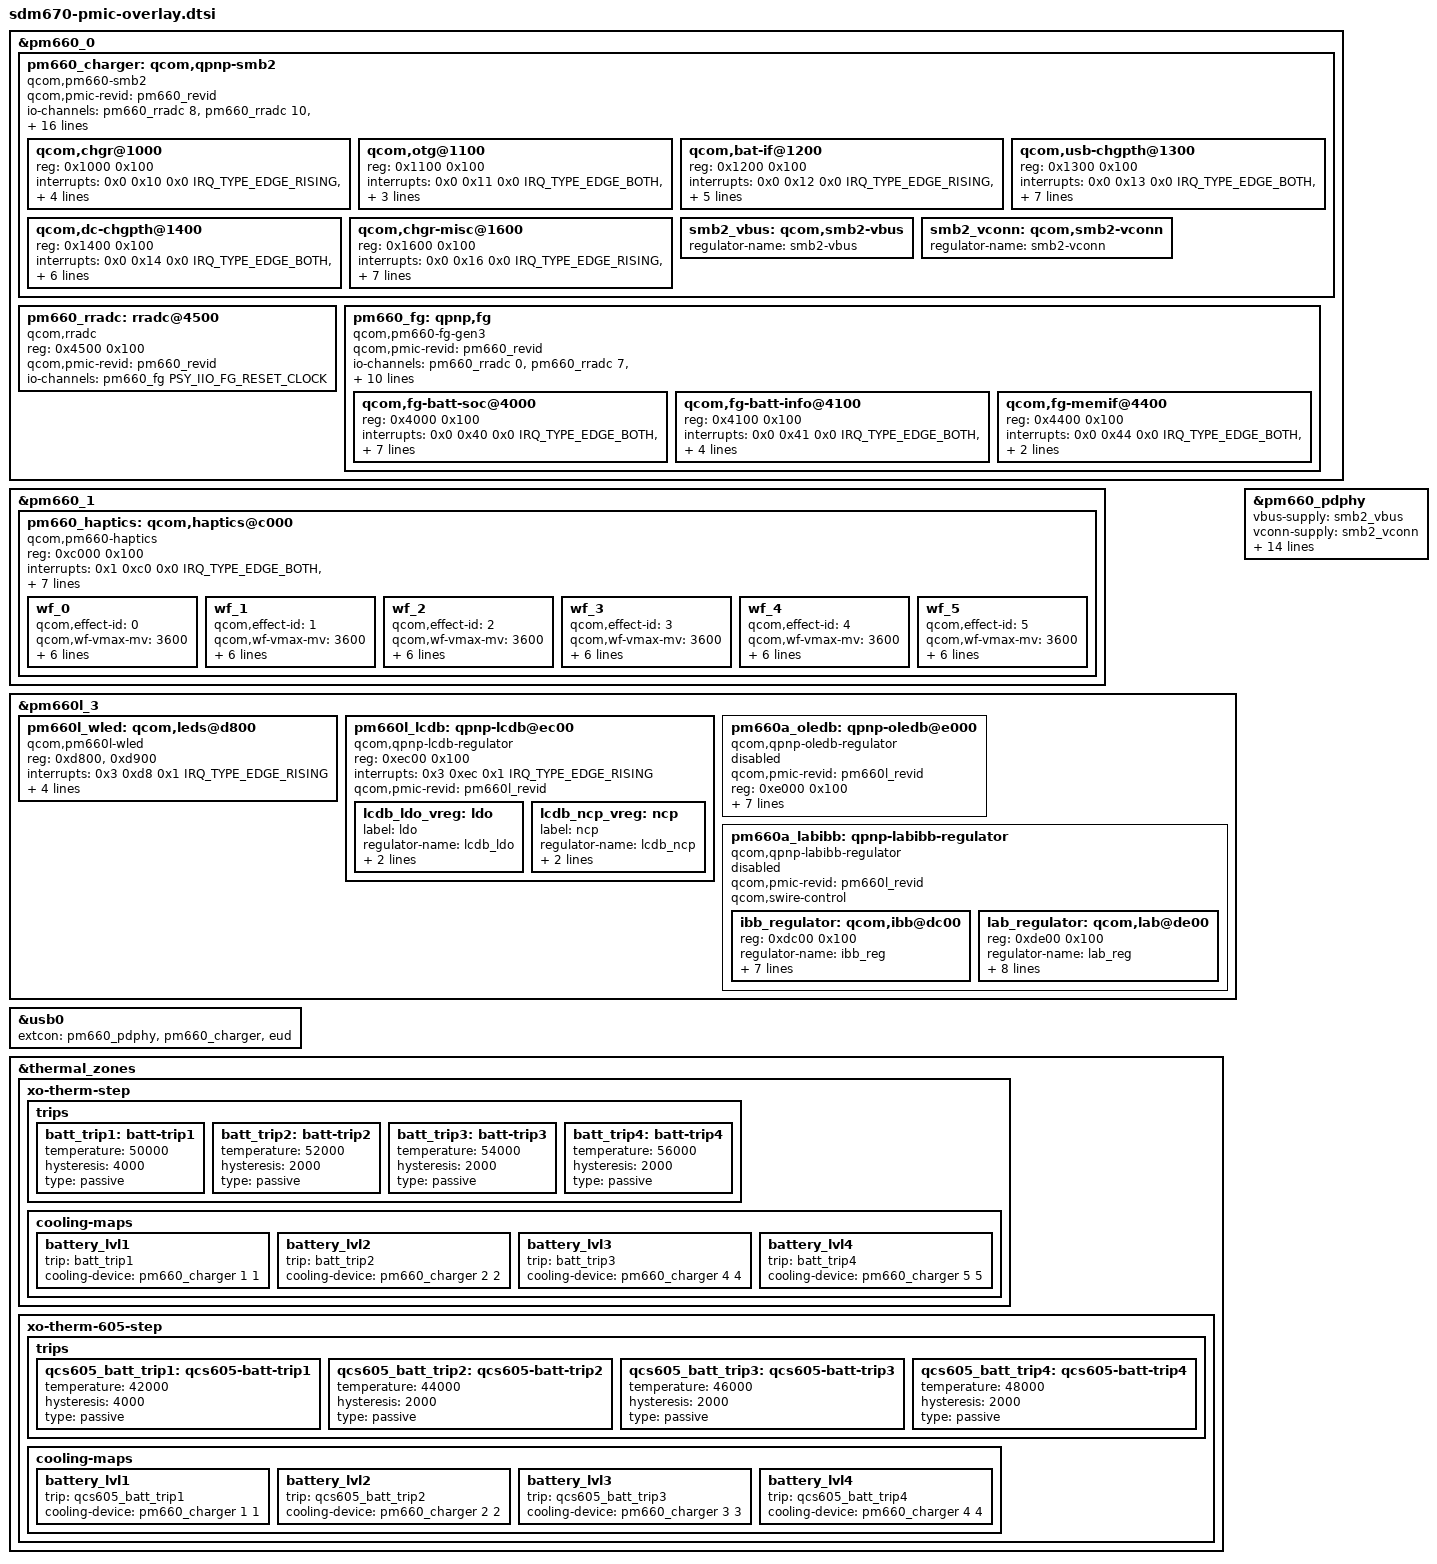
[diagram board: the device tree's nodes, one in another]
#include <dt-bindings/interrupt-controller/arm-gic.h>
#include <dt-bindings/iio/qti_power_supply_iio.h>

&pm660_0 {
	pm660_charger: qcom,qpnp-smb2 {
		compatible = "qcom,pm660-smb2";
		#address-cells = <1>;
		#size-cells = <1>;
		#cooling-cells = <2>;
		#io-channel-cells = <1>;

		qcom,pmic-revid = <&pm660_revid>;

		io-channels = <&pm660_rradc 8>,
			      <&pm660_rradc 10>,
			      <&pm660_rradc 3>,
			      <&pm660_rradc 4>,
			      <&pm660_fg PSY_IIO_DEBUG_BATTERY>,
			      <&pm660_fg PSY_IIO_VOLTAGE_NOW>,
			      <&pm660_fg PSY_IIO_CAPACITY>,
			      <&pm660_fg PSY_IIO_CURRENT_NOW>,
			      <&pm660_fg PSY_IIO_CHARGE_FULL>,
			      <&pm660_fg PSY_IIO_CHARGE_COUNTER>,
			      <&pm660_fg PSY_IIO_CYCLE_COUNT>,
			      <&pm660_fg PSY_IIO_CHARGE_FULL_DESIGN>,
			      <&pm660_fg PSY_IIO_TIME_TO_FULL_NOW>,
			      <&pm660_fg PSY_IIO_TEMP>;
		io-channel-names = "charger_temp",
				   "charger_temp_max",
				   "usbin_i",
				   "usbin_v",
				   "debug_battery",
				   "voltage_now",
				   "capacity",
				   "current_now",
				   "charge_full",
				   "charge_counter",
				   "cycle_count",
				   "charge_full_design",
				   "time_to_full_now",
				   "temp";

		qcom,wipower-max-uw = <5000000>;

		dpdm-supply = <&qusb_phy0>;

		qcom,thermal-mitigation
				= <3000000 2500000 2000000 1500000
					1000000 500000>;
		qcom,auto-recharge-soc;

		qcom,chgr@1000 {
			reg = <0x1000 0x100>;
			interrupts =
				<0x0 0x10 0x0 IRQ_TYPE_EDGE_RISING>,
				<0x0 0x10 0x1 IRQ_TYPE_EDGE_RISING>,
				<0x0 0x10 0x2 IRQ_TYPE_EDGE_RISING>,
				<0x0 0x10 0x3 IRQ_TYPE_EDGE_RISING>,
				<0x0 0x10 0x4 IRQ_TYPE_EDGE_RISING>;

			interrupt-names = "chg-error",
					  "chg-state-change",
					  "step-chg-state-change",
					  "step-chg-soc-update-fail",
					  "step-chg-soc-update-request";
		};

		qcom,otg@1100 {
			reg = <0x1100 0x100>;
			interrupts = <0x0 0x11 0x0 IRQ_TYPE_EDGE_BOTH>,
				     <0x0 0x11 0x1 IRQ_TYPE_EDGE_BOTH>,
				     <0x0 0x11 0x2 IRQ_TYPE_EDGE_BOTH>,
				     <0x0 0x11 0x3 IRQ_TYPE_EDGE_BOTH>;

			interrupt-names = "otg-fail",
					  "otg-overcurrent",
					  "otg-oc-dis-sw-sts",
					  "testmode-change-detect";
		};

		qcom,bat-if@1200 {
			reg = <0x1200 0x100>;
			interrupts =
				<0x0 0x12 0x0 IRQ_TYPE_EDGE_RISING>,
				<0x0 0x12 0x1 IRQ_TYPE_EDGE_BOTH>,
				<0x0 0x12 0x2 IRQ_TYPE_EDGE_BOTH>,
				<0x0 0x12 0x3 IRQ_TYPE_EDGE_BOTH>,
				<0x0 0x12 0x4 IRQ_TYPE_EDGE_BOTH>,
				<0x0 0x12 0x5 IRQ_TYPE_EDGE_BOTH>;

			interrupt-names = "bat-temp",
					  "bat-ocp",
					  "bat-ov",
					  "bat-low",
					  "bat-therm-or-id-missing",
					  "bat-terminal-missing";
		};

		qcom,usb-chgpth@1300 {
			reg = <0x1300 0x100>;
			interrupts =
				<0x0 0x13 0x0 IRQ_TYPE_EDGE_BOTH>,
				<0x0 0x13 0x1 IRQ_TYPE_EDGE_BOTH>,
				<0x0 0x13 0x2 IRQ_TYPE_EDGE_BOTH>,
				<0x0 0x13 0x3 IRQ_TYPE_EDGE_BOTH>,
				<0x0 0x13 0x4 IRQ_TYPE_EDGE_BOTH>,
				<0x0 0x13 0x5 IRQ_TYPE_EDGE_RISING>,
				<0x0 0x13 0x6 IRQ_TYPE_EDGE_RISING>,
				<0x0 0x13 0x7 IRQ_TYPE_EDGE_RISING>;

			interrupt-names = "usbin-collapse",
					  "usbin-lt-3p6v",
					  "usbin-uv",
					  "usbin-ov",
					  "usbin-plugin",
					  "usbin-src-change",
					  "usbin-icl-change",
					  "type-c-change";
		};

		qcom,dc-chgpth@1400 {
			reg = <0x1400 0x100>;
			interrupts =
				<0x0 0x14 0x0 IRQ_TYPE_EDGE_BOTH>,
				<0x0 0x14 0x1 IRQ_TYPE_EDGE_BOTH>,
				<0x0 0x14 0x2 IRQ_TYPE_EDGE_BOTH>,
				<0x0 0x14 0x3 IRQ_TYPE_EDGE_BOTH>,
				<0x0 0x14 0x4 IRQ_TYPE_EDGE_BOTH>,
				<0x0 0x14 0x5 IRQ_TYPE_EDGE_BOTH>,
				<0x0 0x14 0x6 IRQ_TYPE_EDGE_RISING>;

			interrupt-names = "dcin-collapse",
					  "dcin-lt-3p6v",
					  "dcin-uv",
					  "dcin-ov",
					  "dcin-plugin",
					  "div2-en-dg",
					  "dcin-icl-change";
		};

		qcom,chgr-misc@1600 {
			reg = <0x1600 0x100>;
			interrupts =
				<0x0 0x16 0x0 IRQ_TYPE_EDGE_RISING>,
				<0x0 0x16 0x1 IRQ_TYPE_EDGE_RISING>,
				<0x0 0x16 0x2 IRQ_TYPE_EDGE_BOTH>,
				<0x0 0x16 0x3 IRQ_TYPE_EDGE_BOTH>,
				<0x0 0x16 0x4 IRQ_TYPE_EDGE_BOTH>,
				<0x0 0x16 0x5 IRQ_TYPE_EDGE_BOTH>,
				<0x0 0x16 0x6 IRQ_TYPE_EDGE_FALLING>,
				<0x0 0x16 0x7 IRQ_TYPE_EDGE_BOTH>;

			interrupt-names = "wdog-snarl",
					  "wdog-bark",
					  "aicl-fail",
					  "aicl-done",
					  "high-duty-cycle",
					  "input-current-limiting",
					  "temperature-change",
					  "switcher-power-ok";
		};

		smb2_vbus: qcom,smb2-vbus {
			regulator-name = "smb2-vbus";
		};

		smb2_vconn: qcom,smb2-vconn {
			regulator-name = "smb2-vconn";
		};
	};

	pm660_rradc: rradc@4500 {
		compatible = "qcom,rradc";
		reg = <0x4500 0x100>;
		#address-cells = <1>;
		#size-cells = <0>;
		#io-channel-cells = <1>;

		qcom,pmic-revid = <&pm660_revid>;
		io-channels = <&pm660_fg PSY_IIO_FG_RESET_CLOCK>;
		io-channel-names = "fg_reset_clock";
	};

	pm660_fg: qpnp,fg {
		compatible = "qcom,pm660-fg-gen3";
		#address-cells = <1>;
		#size-cells = <1>;
		#io-channel-cells = <1>;

		qcom,pmic-revid = <&pm660_revid>;
		io-channels = <&pm660_rradc 0>,
			      <&pm660_rradc 7>,
			      <&pm660_charger PSY_IIO_CHARGE_QNOVO_ENABLE>,
			      <&pm660_charger PSY_IIO_CHARGE_DONE>;
		io-channel-names = "rradc_batt_id",
				   "rradc_die_temp",
				   "charge_qnovo_enable",
				   "charge_done";
		qcom,rradc-base = <0x4500>;
		qcom,fg-esr-timer-awake = <64 96>;
		qcom,fg-esr-timer-asleep = <224 256>;
		qcom,fg-esr-timer-charging = <0 96>;
		qcom,cycle-counter-en;
		qcom,hold-soc-while-full;
		qcom,fg-auto-recharge-soc;
		qcom,fg-recharge-soc-thr = <98>;
		status = "okay";

		qcom,fg-batt-soc@4000 {
			status = "okay";
			reg = <0x4000 0x100>;
			interrupts = <0x0 0x40 0x0 IRQ_TYPE_EDGE_BOTH>,
				     <0x0 0x40 0x1 IRQ_TYPE_EDGE_BOTH>,
				     <0x0 0x40 0x2
						IRQ_TYPE_EDGE_RISING>,
				     <0x0 0x40 0x3
						IRQ_TYPE_EDGE_RISING>,
				     <0x0 0x40 0x4 IRQ_TYPE_EDGE_BOTH>,
				     <0x0 0x40 0x5
						IRQ_TYPE_EDGE_RISING>,
				     <0x0 0x40 0x6 IRQ_TYPE_EDGE_BOTH>,
				     <0x0 0x40 0x7 IRQ_TYPE_EDGE_BOTH>;
			interrupt-names = "soc-update",
					  "soc-ready",
					  "bsoc-delta",
					  "msoc-delta",
					  "msoc-low",
					  "msoc-empty",
					  "msoc-high",
					  "msoc-full";
		};

		qcom,fg-batt-info@4100 {
			status = "okay";
			reg = <0x4100 0x100>;
			interrupts = <0x0 0x41 0x0 IRQ_TYPE_EDGE_BOTH>,
				     <0x0 0x41 0x1 IRQ_TYPE_EDGE_BOTH>,
				     <0x0 0x41 0x2 IRQ_TYPE_EDGE_BOTH>,
				     <0x0 0x41 0x3 IRQ_TYPE_EDGE_BOTH>,
				     <0x0 0x41 0x6 IRQ_TYPE_EDGE_BOTH>;
			interrupt-names = "vbatt-pred-delta",
					  "vbatt-low",
					  "esr-delta",
					  "batt-missing",
					  "batt-temp-delta";
		};

		qcom,fg-memif@4400 {
			status = "okay";
			reg = <0x4400 0x100>;
			interrupts = <0x0 0x44 0x0 IRQ_TYPE_EDGE_BOTH>,
				     <0x0 0x44 0x1 IRQ_TYPE_EDGE_BOTH>,
				     <0x0 0x44 0x2 IRQ_TYPE_EDGE_BOTH>;
			interrupt-names = "ima-rdy",
					  "mem-xcp",
					  "dma-grant";
		};
	};
};

&pm660_1 {
	pm660_haptics: qcom,haptics@c000 {
		compatible = "qcom,pm660-haptics";
		reg = <0xc000 0x100>;
		interrupts = <0x1 0xc0 0x0 IRQ_TYPE_EDGE_BOTH>,
			     <0x1 0xc0 0x1 IRQ_TYPE_EDGE_BOTH>;
		interrupt-names = "hap-sc-irq", "hap-play-irq";
		qcom,actuator-type = "lra";
		qcom,vmax-mv = <3200>;
		qcom,play-rate-us = <6667>;
		qcom,lra-resonance-sig-shape = "sine";
		qcom,lra-auto-resonance-mode = "qwd";
		qcom,lra-allow-variable-play-rate;

		wf_0 {
			/* CLICK */
			qcom,effect-id = <0>;
			qcom,wf-vmax-mv = <3600>;
			qcom,wf-pattern = [3e 3e 3e 3e 3e 3e 3e 3e];
			qcom,wf-play-rate-us = <6667>;
			qcom,wf-brake-pattern = [00 00 00 00];
			qcom,wf-repeat-count = <1>;
			qcom,wf-s-repeat-count = <1>;
			qcom,lra-auto-resonance-disable;
		};

		wf_1 {
			/* DOUBLE CLICK */
			qcom,effect-id = <1>;
			qcom,wf-vmax-mv = <3600>;
			qcom,wf-pattern = [3e 3e 3e 3e 3e 3e 3e 3e];
			qcom,wf-play-rate-us = <6667>;
			qcom,wf-brake-pattern = [00 00 00 00];
			qcom,wf-repeat-count = <1>;
			qcom,wf-s-repeat-count = <1>;
			qcom,lra-auto-resonance-disable;
		};

		wf_2 {
			/* TICK */
			qcom,effect-id = <2>;
			qcom,wf-vmax-mv = <3600>;
			qcom,wf-pattern = [3e 3e 3e 3e 3e 3e 3e 3e];
			qcom,wf-play-rate-us = <6667>;
			qcom,wf-brake-pattern = [00 00 00 00];
			qcom,wf-repeat-count = <1>;
			qcom,wf-s-repeat-count = <1>;
			qcom,lra-auto-resonance-disable;
		};

		wf_3 {
			/* THUD */
			qcom,effect-id = <3>;
			qcom,wf-vmax-mv = <3600>;
			qcom,wf-pattern = [3e 3e 3e 3e 3e 3e 3e 3e];
			qcom,wf-play-rate-us = <6667>;
			qcom,wf-brake-pattern = [00 00 00 00];
			qcom,wf-repeat-count = <1>;
			qcom,wf-s-repeat-count = <1>;
			qcom,lra-auto-resonance-disable;
		};

		wf_4 {
			/* POP */
			qcom,effect-id = <4>;
			qcom,wf-vmax-mv = <3600>;
			qcom,wf-pattern = [3e 3e 3e 3e 3e 3e 3e 3e];
			qcom,wf-play-rate-us = <6667>;
			qcom,wf-brake-pattern = [00 00 00 00];
			qcom,wf-repeat-count = <1>;
			qcom,wf-s-repeat-count = <1>;
			qcom,lra-auto-resonance-disable;
		};

		wf_5 {
			/* HEAVY CLICK */
			qcom,effect-id = <5>;
			qcom,wf-vmax-mv = <3600>;
			qcom,wf-pattern = [3e 3e 3e 3e 3e 3e 3e 3e];
			qcom,wf-play-rate-us = <6667>;
			qcom,wf-brake-pattern = [00 00 00 00];
			qcom,wf-repeat-count = <1>;
			qcom,wf-s-repeat-count = <1>;
			qcom,lra-auto-resonance-disable;
		};
	};
};

&pm660l_3 {
	pm660l_wled: qcom,leds@d800 {
		compatible = "qcom,pm660l-wled";
		reg = <0xd800>, <0xd900>;
		reg-names = "wled-ctrl-base",
				"wled-sink-base";
		interrupts = <0x3 0xd8 0x1 IRQ_TYPE_EDGE_RISING>;
		interrupt-names = "ovp-irq";
		label = "backlight";
		qcom,pmic-revid = <&pm660l_revid>;
		qcom,auto-calibration;
		status = "ok";
		qcom,enabled-strings = <0 1 2 3>;
	};

	pm660l_lcdb: qpnp-lcdb@ec00 {
		compatible = "qcom,qpnp-lcdb-regulator";
		#address-cells = <1>;
		#size-cells = <1>;
		reg = <0xec00 0x100>;
		interrupts = <0x3 0xec 0x1 IRQ_TYPE_EDGE_RISING>;
		interrupt-names = "sc-irq";

		qcom,pmic-revid = <&pm660l_revid>;

		lcdb_ldo_vreg: ldo {
			label = "ldo";
			regulator-name = "lcdb_ldo";
			regulator-min-microvolt = <4000000>;
			regulator-max-microvolt = <6000000>;
		};

		lcdb_ncp_vreg: ncp {
			label = "ncp";
			regulator-name = "lcdb_ncp";
			regulator-min-microvolt = <4000000>;
			regulator-max-microvolt = <6000000>;
		};
	};

	pm660a_oledb: qpnp-oledb@e000 {
	       compatible = "qcom,qpnp-oledb-regulator";
	       #address-cells = <1>;
	       #size-cells = <1>;
	       qcom,pmic-revid = <&pm660l_revid>;
	       reg = <0xe000 0x100>;
	       qcom,pbs-client = <&pm660l_pbs>;

	       label = "oledb";
	       regulator-name = "regulator-oledb";
	       regulator-min-microvolt = <5000000>;
	       regulator-max-microvolt = <8100000>;

	       qcom,swire-control;
	       qcom,ext-pin-control;
	       status = "disabled";
	};

	pm660a_labibb: qpnp-labibb-regulator {
		compatible = "qcom,qpnp-labibb-regulator";
		#address-cells = <1>;
		#size-cells = <1>;
		qcom,pmic-revid = <&pm660l_revid>;
		qcom,swire-control;
		status = "disabled";

		ibb_regulator: qcom,ibb@dc00 {
			reg = <0xdc00 0x100>;
			reg-names = "ibb_reg";
			regulator-name = "ibb_reg";

			regulator-min-microvolt = <4000000>;
			regulator-max-microvolt = <6300000>;

			qcom,qpnp-ibb-min-voltage = <1400000>;
			qcom,qpnp-ibb-step-size = <100000>;
			qcom,qpnp-ibb-slew-rate = <2000000>;
			qcom,qpnp-ibb-init-voltage = <4000000>;
			qcom,qpnp-ibb-init-amoled-voltage = <4000000>;
		};

		lab_regulator: qcom,lab@de00 {
			reg = <0xde00 0x100>;
			reg-names = "lab";
			regulator-name = "lab_reg";

			regulator-min-microvolt = <4600000>;
			regulator-max-microvolt = <6100000>;

			qcom,qpnp-lab-min-voltage = <4600000>;
			qcom,qpnp-lab-step-size = <100000>;
			qcom,qpnp-lab-slew-rate = <5000>;
			qcom,qpnp-lab-init-voltage = <4600000>;
			qcom,qpnp-lab-init-amoled-voltage = <4600000>;

			qcom,notify-lab-vreg-ok-sts;
		};
	};
};

&pm660_pdphy {
	vbus-supply = <&smb2_vbus>;
	vconn-supply = <&smb2_vconn>;

	#io-channel-cells = <1>;
	io-channels = <&pm660_charger PSY_IIO_PD_ACTIVE>,
		      <&pm660_charger PSY_IIO_TYPEC_CC_ORIENTATION>,
		      <&pm660_charger PSY_IIO_CONNECTOR_TYPE>,
		      <&pm660_charger PSY_IIO_TYPEC_POWER_ROLE>,
		      <&pm660_charger PSY_IIO_PD_USB_SUSPEND_SUPPORTED>,
		      <&pm660_charger PSY_IIO_TYPEC_SRC_RP>,
		      <&pm660_charger PSY_IIO_PD_IN_HARD_RESET>,
		      <&pm660_charger PSY_IIO_PD_CURRENT_MAX>,
		      <&pm660_charger PSY_IIO_PR_SWAP>,
		      <&pm660_charger PSY_IIO_PD_VOLTAGE_MIN>,
		      <&pm660_charger PSY_IIO_PD_VOLTAGE_MAX>,
		      <&pm660_charger PSY_IIO_USB_REAL_TYPE>,
		      <&pm660_charger PSY_IIO_TYPEC_MODE>,
		      <&pm660_charger PSY_IIO_PE_START>;
	io-channel-names = "pd_active",
			   "typec_cc_orientation",
			   "connector_type",
			   "typec_power_role",
			   "pd_usb_suspend_supported",
			   "typec_src_rp",
			   "pd_in_hard_reset",
			   "pr_current_max",
			   "pr_swap",
			   "pd_voltage_min",
			   "pd_voltage_max",
			   "real_type",
			   "typec_mode",
			   "pe_start";
};

&usb0 {
	extcon = <&pm660_pdphy>, <&pm660_charger>, <&eud>;
};

&thermal_zones {
	xo-therm-step {
		trips {
			batt_trip1: batt-trip1 {
				temperature = <50000>;
				hysteresis = <4000>;
				type = "passive";
			};

			batt_trip2: batt-trip2 {
				temperature = <52000>;
				hysteresis = <2000>;
				type = "passive";
			};

			batt_trip3: batt-trip3 {
				temperature = <54000>;
				hysteresis = <2000>;
				type = "passive";
			};

			batt_trip4: batt-trip4 {
				temperature = <56000>;
				hysteresis = <2000>;
				type = "passive";
			};
		};

		cooling-maps {
			battery_lvl1 {
				trip = <&batt_trip1>;
				cooling-device = <&pm660_charger 1 1>;
			};

			battery_lvl2 {
				trip = <&batt_trip2>;
				cooling-device = <&pm660_charger 2 2>;
			};

			battery_lvl3 {
				trip = <&batt_trip3>;
				cooling-device = <&pm660_charger 4 4>;
			};

			battery_lvl4 {
				trip = <&batt_trip4>;
				cooling-device = <&pm660_charger 5 5>;
			};
		};
	};

	xo-therm-605-step {
		trips {
			qcs605_batt_trip1: qcs605-batt-trip1 {
				temperature = <42000>;
				hysteresis = <4000>;
				type = "passive";
			};

			qcs605_batt_trip2: qcs605-batt-trip2 {
				temperature = <44000>;
				hysteresis = <2000>;
				type = "passive";
			};

			qcs605_batt_trip3: qcs605-batt-trip3 {
				temperature = <46000>;
				hysteresis = <2000>;
				type = "passive";
			};

			qcs605_batt_trip4: qcs605-batt-trip4 {
				temperature = <48000>;
				hysteresis = <2000>;
				type = "passive";
			};
		};

		cooling-maps {
			battery_lvl1 {
				trip = <&qcs605_batt_trip1>;
				cooling-device = <&pm660_charger 1 1>;
			};

			battery_lvl2 {
				trip = <&qcs605_batt_trip2>;
				cooling-device = <&pm660_charger 2 2>;
			};

			battery_lvl3 {
				trip = <&qcs605_batt_trip3>;
				cooling-device = <&pm660_charger 3 3>;
			};

			battery_lvl4 {
				trip = <&qcs605_batt_trip4>;
				cooling-device = <&pm660_charger 4 4>;
			};
		};
	};
};
